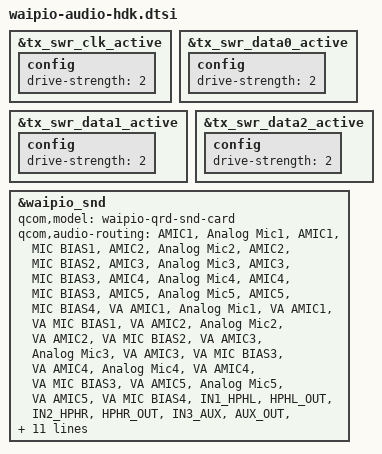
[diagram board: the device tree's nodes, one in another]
#include "waipio-audio-overlay.dtsi"
&tx_swr_clk_active {
	config {
		drive-strength = <2>;
	};
};

&tx_swr_data0_active {
	config {
		drive-strength = <2>;
	};
};

&tx_swr_data1_active {
	config {
		drive-strength = <2>;
	};
};

&tx_swr_data2_active {
	config {
		drive-strength = <2>;
	};
};

&waipio_snd {
	qcom,model = "waipio-qrd-snd-card";

	qcom,audio-routing =
		"AMIC1", "Analog Mic1",
		"AMIC1", "MIC BIAS1",
		"AMIC2", "Analog Mic2",
		"AMIC2", "MIC BIAS2",
		"AMIC3", "Analog Mic3",
		"AMIC3", "MIC BIAS3",
		"AMIC4", "Analog Mic4",
		"AMIC4", "MIC BIAS3",
		"AMIC5", "Analog Mic5",
		"AMIC5", "MIC BIAS4",
		"VA AMIC1", "Analog Mic1",
		"VA AMIC1", "VA MIC BIAS1",
		"VA AMIC2", "Analog Mic2",
		"VA AMIC2", "VA MIC BIAS2",
		"VA AMIC3", "Analog Mic3",
		"VA AMIC3", "VA MIC BIAS3",
		"VA AMIC4", "Analog Mic4",
		"VA AMIC4", "VA MIC BIAS3",
		"VA AMIC5", "Analog Mic5",
		"VA AMIC5", "VA MIC BIAS4",
		"IN1_HPHL", "HPHL_OUT",
		"IN2_HPHR", "HPHR_OUT",
		"IN3_AUX", "AUX_OUT",
		"HAP_IN", "PCM_OUT",
		"WSA SRC0_INP", "SRC0",
		"WSA_TX DEC0_INP", "TX DEC0 MUX",
		"WSA_TX DEC1_INP", "TX DEC1 MUX",
		"RX_TX DEC0_INP", "TX DEC0 MUX",
		"RX_TX DEC1_INP", "TX DEC1 MUX",
		"RX_TX DEC2_INP", "TX DEC2 MUX",
		"RX_TX DEC3_INP", "TX DEC3 MUX",
		"SpkrLeft IN", "WSA_SPK1 OUT",
		"SpkrRight IN", "WSA_SPK2 OUT",
		"TX SWR_INPUT", "WCD_TX_OUTPUT",
		"VA SWR_INPUT", "VA_SWR_CLK",
		"VA SWR_INPUT", "WCD_TX_OUTPUT",
		"VA_AIF1 CAP", "VA_SWR_CLK",
		"VA_AIF2 CAP", "VA_SWR_CLK",
		"VA_AIF3 CAP", "VA_SWR_CLK";
};

